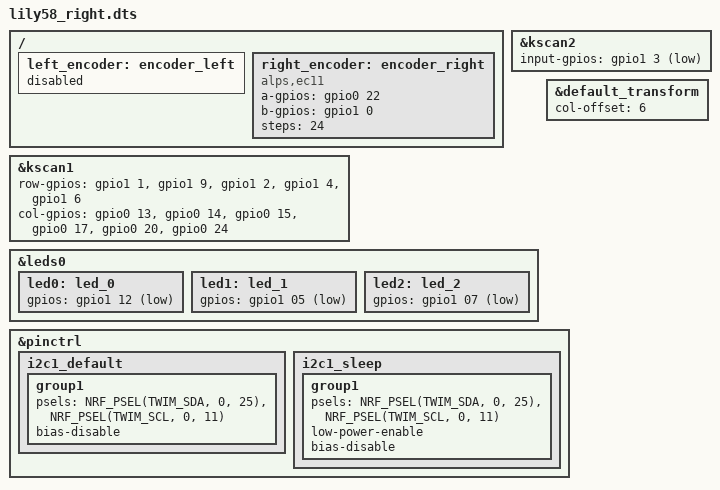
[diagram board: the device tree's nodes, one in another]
#include "lily58.dtsi"

/ {
    left_encoder: encoder_left {
        status = "disabled";
    };

    right_encoder: encoder_right {
        compatible = "alps,ec11";
        a-gpios = <&gpio0 22 (GPIO_ACTIVE_HIGH | GPIO_PULL_UP)>;
        b-gpios = <&gpio1 0 (GPIO_ACTIVE_HIGH | GPIO_PULL_UP)>;
        steps = <24>;
    };
};


&kscan1 {
    row-gpios
        = <&gpio1 1 (GPIO_ACTIVE_HIGH | GPIO_PULL_DOWN)>
        , <&gpio1 9 (GPIO_ACTIVE_HIGH | GPIO_PULL_DOWN)>
        , <&gpio1 2 (GPIO_ACTIVE_HIGH | GPIO_PULL_DOWN)>
        , <&gpio1 4 (GPIO_ACTIVE_HIGH | GPIO_PULL_DOWN)>
        , <&gpio1 6 (GPIO_ACTIVE_HIGH | GPIO_PULL_DOWN)>
        ;

    col-gpios
        = <&gpio0 13 GPIO_ACTIVE_HIGH>
        , <&gpio0 14 GPIO_ACTIVE_HIGH>
        , <&gpio0 15 GPIO_ACTIVE_HIGH>
        , <&gpio0 17 GPIO_ACTIVE_HIGH>
        , <&gpio0 20 GPIO_ACTIVE_HIGH>
        , <&gpio0 24 GPIO_ACTIVE_HIGH>
        ;
};

&kscan2 {
        input-gpios
            = <&gpio1 3 (GPIO_ACTIVE_LOW | GPIO_PULL_UP)>
            ;
};

&leds0 {
    led0: led_0 {
        gpios = <&gpio1 12 GPIO_ACTIVE_LOW>;  // red LED
    };
    led1: led_1 {
        gpios = <&gpio1 05 GPIO_ACTIVE_LOW>;  // green LED
    };
    led2: led_2 {
        gpios = <&gpio1 07 GPIO_ACTIVE_LOW>;  // blue LED
    };
};

&default_transform {
	col-offset = <6>;
};

&pinctrl {
    i2c1_default: i2c1_default {
        group1 {
            psels = <NRF_PSEL(TWIM_SDA, 0, 25)>,
                    <NRF_PSEL(TWIM_SCL, 0, 11)>;
            bias-disable;
        };
    };

    i2c1_sleep: i2c1_sleep {
        group1 {
            psels = <NRF_PSEL(TWIM_SDA, 0, 25)>,
                    <NRF_PSEL(TWIM_SCL, 0, 11)>;
            low-power-enable;
            bias-disable;
        };
    };
};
